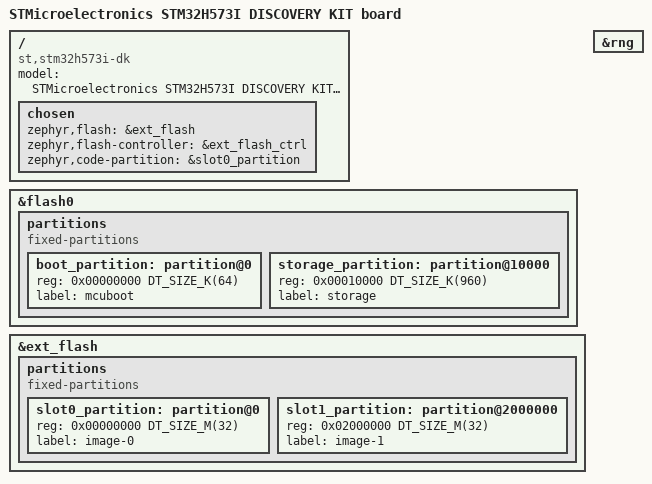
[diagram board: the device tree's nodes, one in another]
/*
 * Copyright (c) 2023 STMicroelectronics
 *
 * SPDX-License-Identifier: Apache-2.0
 */

/dts-v1/;
#include "stm32h573i_dk-common.dtsi"

/ {
	compatible = "st,stm32h573i-dk";
	model = "STMicroelectronics STM32H573I DISCOVERY KIT board";

	chosen {
		zephyr,flash = &ext_flash;
		zephyr,flash-controller = &ext_flash_ctrl;
		zephyr,code-partition = &slot0_partition;
	};
};

&flash0 {
	partitions {
		compatible = "fixed-partitions";
		#address-cells = <1>;
		#size-cells = <1>;

		/* Set the partitions with first MB to make use of the whole Bank1 */
		boot_partition: partition@0 {
			reg = <0x00000000 DT_SIZE_K(64)>;
			label = "mcuboot";
		};

		storage_partition: partition@10000 {
			reg = <0x00010000 DT_SIZE_K(960)>;
			label = "storage";
		};
	};
};

&ext_flash {
	partitions {
		compatible = "fixed-partitions";
		#address-cells = <1>;
		#size-cells = <1>;

		slot0_partition: partition@0 {
			reg = <0x00000000 DT_SIZE_M(32)>;
			label = "image-0";
		};

		slot1_partition: partition@2000000 {
			reg = <0x02000000 DT_SIZE_M(32)>;
			label = "image-1";
		};
	};
};

&rng {
	status = "okay";
};
